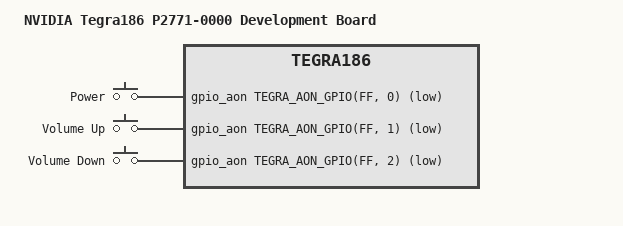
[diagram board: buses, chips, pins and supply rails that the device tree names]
/dts-v1/;

#include <dt-bindings/input/linux-event-codes.h>

#include "tegra186-p3310.dtsi"

/ {
	model = "NVIDIA Tegra186 P2771-0000 Development Board";
	compatible = "nvidia,p2771-0000", "nvidia,tegra186";

	gpio-keys {
		compatible = "gpio-keys";

		power {
			label = "Power";
			gpios = <&gpio_aon TEGRA_AON_GPIO(FF, 0)
					   GPIO_ACTIVE_LOW>;
			linux,input-type = <EV_KEY>;
			linux,code = <KEY_POWER>;
			debounce-interval = <10>;
			wakeup-source;
		};

		volume-up {
			label = "Volume Up";
			gpios = <&gpio_aon TEGRA_AON_GPIO(FF, 1)
					   GPIO_ACTIVE_LOW>;
			linux,input-type = <EV_KEY>;
			linux,code = <KEY_VOLUMEUP>;
			debounce-interval = <10>;
		};

		volume-down {
			label = "Volume Down";
			gpios = <&gpio_aon TEGRA_AON_GPIO(FF, 2)
					   GPIO_ACTIVE_LOW>;
			linux,input-type = <EV_KEY>;
			linux,code = <KEY_VOLUMEDOWN>;
			debounce-interval = <10>;
		};
	};
};
